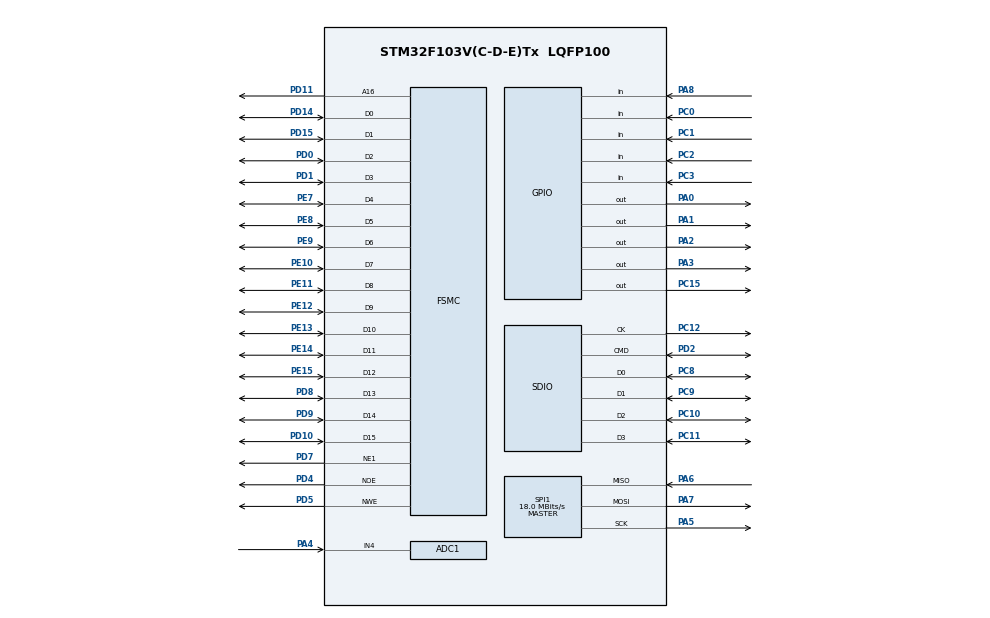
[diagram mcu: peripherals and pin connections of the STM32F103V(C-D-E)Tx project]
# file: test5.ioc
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ADC1.Channel-0\#ChannelRegularConversion=ADC_CHANNEL_4
ADC1.NbrOfConversionFlag=1
ADC1.Rank-0\#ChannelRegularConversion=1
ADC1.SamplingTime-0\#ChannelRegularConversion=ADC_SAMPLETIME_1CYCLE_5
ADC1.master=1
FATFS.BSP.number=1
FATFS._CODE_PAGE=936
FATFS._USE_LFN=2
FATFS0.BSP.STBoard=false
FATFS0.BSP.api=Unknown
FATFS0.BSP.i2caddr=0
FATFS0.BSP.instance=PA8
FATFS0.BSP.ip=GPIO
FATFS0.BSP.mode=Input
FATFS0.BSP.name=Detect_SDIO
FATFS0.BSP.solution=PA8
FREERTOS.Tasks01=defaultTask,24,128,StartDefaultTask,Default,NULL,Dynamic,NULL,NULL
FREERTOS.configUSE_NEWLIB_REENTRANT=1
FSMC.AddressSetupTime1=1
FSMC.BusTurnAroundDuration1=0
FSMC.DataSetupTime1=16
Mcu.Family=STM32F1
Mcu.Name=STM32F103V(C-D-E)Tx
Mcu.Package=LQFP100
NVIC.PriorityGroup=NVIC_PRIORITYGROUP_4
NVIC.TIM1_UP_IRQn=true\:15\:0\:false\:false\:true\:false\:false\:true
NVIC.TimeBase=TIM1_UP_IRQn
NVIC.TimeBaseIP=TIM1
OSC_IN.Mode=HSE-External-Clock-Source
OSC_IN.Signal=RCC_OSC_IN
OSC_OUT.Mode=HSE-External-Clock-Source
OSC_OUT.Signal=RCC_OSC_OUT
PA0-WKUP.GPIO_ModeDefaultOutputPP=GPIO_MODE_OUTPUT_PP
PA0-WKUP.GPIO_PuPd=GPIO_PULLUP
PA0-WKUP.GPIO_Speed=GPIO_SPEED_FREQ_HIGH
PA0-WKUP.PinState=GPIO_PIN_SET
PA0-WKUP.Signal=GPIO_Output
PA1.GPIO_ModeDefaultOutputPP=GPIO_MODE_OUTPUT_PP
PA1.GPIO_PuPd=GPIO_PULLUP
PA1.GPIO_Speed=GPIO_SPEED_FREQ_HIGH
PA1.PinState=GPIO_PIN_SET
PA1.Signal=GPIO_Output
PA13.Mode=Serial_Wire
PA13.Signal=SYS_JTMS-SWDIO
PA14.Mode=Serial_Wire
PA14.Signal=SYS_JTCK-SWCLK
PA2.GPIO_ModeDefaultOutputPP=GPIO_MODE_OUTPUT_PP
PA2.GPIO_PuPd=GPIO_PULLUP
PA2.GPIO_Speed=GPIO_SPEED_FREQ_HIGH
PA2.PinState=GPIO_PIN_SET
PA2.Signal=GPIO_Output
PA3.GPIO_ModeDefaultOutputPP=GPIO_MODE_OUTPUT_PP
PA3.GPIO_PuPd=GPIO_PULLUP
PA3.GPIO_Speed=GPIO_SPEED_FREQ_HIGH
PA3.PinState=GPIO_PIN_SET
PA3.Signal=GPIO_Output
PA4.Signal=ADCx_IN4
PA5.Mode=Full_Duplex_Master
PA5.Signal=SPI1_SCK
PA6.Mode=Full_Duplex_Master
PA6.Signal=SPI1_MISO
PA7.Mode=Full_Duplex_Master
PA7.Signal=SPI1_MOSI
PA8.GPIO_PuPd=GPIO_PULLDOWN
PA8.Signal=GPIO_Input
PC0.GPIO_Mode=GPIO_MODE_INPUT
PC0.GPIO_PuPd=GPIO_PULLUP
PC0.Signal=GPIO_Input
PC1.GPIO_Mode=GPIO_MODE_INPUT
PC1.GPIO_PuPd=GPIO_PULLUP
PC1.Signal=GPIO_Input
PC10.Mode=SD_4_bits_Wide_bus
PC10.Signal=SDIO_D2
PC11.Mode=SD_4_bits_Wide_bus
PC11.Signal=SDIO_D3
PC12.Mode=SD_4_bits_Wide_bus
PC12.Signal=SDIO_CK
PC15-OSC32_OUT.GPIO_PuPd=GPIO_PULLUP
PC15-OSC32_OUT.GPIO_Speed=GPIO_SPEED_FREQ_HIGH
PC15-OSC32_OUT.PinState=GPIO_PIN_SET
PC15-OSC32_OUT.Signal=GPIO_Output
PC2.GPIO_Mode=GPIO_MODE_INPUT
PC2.GPIO_PuPd=GPIO_PULLUP
PC2.Signal=GPIO_Input
PC3.GPIO_Mode=GPIO_MODE_INPUT
PC3.GPIO_PuPd=GPIO_PULLUP
PC3.Signal=GPIO_Input
PC8.Mode=SD_4_bits_Wide_bus
PC8.Signal=SDIO_D0
PC9.Mode=SD_4_bits_Wide_bus
PC9.Signal=SDIO_D1
PD0.Mode=16b-d1
PD0.Signal=FSMC_D2
PD1.Mode=16b-d1
PD1.Signal=FSMC_D3
PD10.Mode=16b-d1
PD10.Signal=FSMC_D15
PD11.Mode=A16_1
PD11.Signal=FSMC_A16
PD14.Mode=16b-d1
PD14.Signal=FSMC_D0
PD15.Mode=16b-d1
PD15.Signal=FSMC_D1
PD2.Mode=SD_4_bits_Wide_bus
PD2.Signal=SDIO_CMD
PD4.Mode=Lcd1
PD4.Signal=FSMC_NOE
PD5.Mode=Lcd1
PD5.Signal=FSMC_NWE
PD7.Mode=NorPsramChipSelect1_1
PD7.Signal=FSMC_NE1
PD8.Mode=16b-d1
PD8.Signal=FSMC_D13
PD9.Mode=16b-d1
PD9.Signal=FSMC_D14
PE10.Mode=16b-d1
PE10.Signal=FSMC_D7
PE11.Mode=16b-d1
PE11.Signal=FSMC_D8
PE12.Mode=16b-d1
PE12.Signal=FSMC_D9
PE13.Mode=16b-d1
PE13.Signal=FSMC_D10
PE14.Mode=16b-d1
PE14.Signal=FSMC_D11
PE15.Mode=16b-d1
PE15.Signal=FSMC_D12
PE7.Mode=16b-d1
PE7.Signal=FSMC_D4
PE8.Mode=16b-d1
PE8.Signal=FSMC_D5
PE9.Mode=16b-d1
PE9.Signal=FSMC_D6
ProjectManager.HeapSize=0x200
ProjectManager.StackSize=0x800
ProjectManager.TargetToolchain=STM32CubeIDE
RCC.ADCPresc=RCC_ADCPCLK2_DIV6
RCC.AHBFreq_Value=72000000
RCC.APB1CLKDivider=RCC_HCLK_DIV2
RCC.APB1Freq_Value=36000000
RCC.APB1TimFreq_Value=72000000
RCC.APB2Freq_Value=72000000
RCC.APB2TimFreq_Value=72000000
RCC.EnbaleCSS=true
RCC.HCLKFreq_Value=72000000
RCC.PLLMUL=RCC_PLL_MUL9
RCC.PLLSourceVirtual=RCC_PLLSOURCE_HSE
RCC.SYSCLKFreq_VALUE=72000000
RCC.SYSCLKSource=RCC_SYSCLKSOURCE_PLLCLK
RCC.USBFreq_Value=72000000
SH.ADCx_IN4.0=ADC1_IN4,IN4
SPI1.BaudRatePrescaler=SPI_BAUDRATEPRESCALER_4
SPI1.CLKPhase=SPI_PHASE_2EDGE
SPI1.CLKPolarity=SPI_POLARITY_HIGH
SPI1.CRCCalculation=SPI_CRCCALCULATION_DISABLE
SPI1.CalculateBaudRate=18.0 MBits/s
SPI1.Direction=SPI_DIRECTION_2LINES
SPI1.Mode=SPI_MODE_MASTER
SPI1.VirtualType=VM_MASTER
VP_CRC_VS_CRC.Mode=CRC_Activate
VP_FATFS_VS_SDIO.Mode=SDIO
VP_FREERTOS_VS_CMSIS_V2.Mode=CMSIS_V2
VP_SYS_VS_tim1.Mode=TIM1
board=custom

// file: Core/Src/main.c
/* USER CODE BEGIN Header */
/**
  ******************************************************************************
  * @file           : main.c
  * @brief          : Main program body
  ******************************************************************************
  * @attention
  *
  * <h2><center>&copy; Copyright (c) 2021 STMicroelectronics.
  * All rights reserved.</center></h2>
  *
  * This software component is licensed by ST under Ultimate Liberty license
  * SLA0044, the "License"; You may not use this file except in compliance with
  * the License. You may obtain a copy of the License at:
  *                             www.st.com/SLA0044
  *
  ******************************************************************************
  */
/* USER CODE END Header */
#include "main.h"
#include "cmsis_os.h"
#include "fatfs.h"
#include "exfuns/exfuns.h"
#include "lcd/lcd.h"
#include "mp3player/mp3player.h"
#include "show/show.h"

SD_HandleTypeDef hsd;

SRAM_HandleTypeDef hsram1;

/* Definitions for defaultTask */
osThreadId_t defaultTaskHandle;
const osThreadAttr_t defaultTask_attributes = {
    .name = "defaultTask",
    .stack_size = 128 * 4,
    .priority = (osPriority_t)osPriorityNormal,
};
osThreadId_t mp3TaskHandle;
const osThreadAttr_t mp3Task_attributes = {
    .name = "mp3 Task",
    .stack_size = 128 * 4,
    .priority = (osPriority_t)osPriorityNormal,
};
osThreadId_t showTaskHandle;
const osThreadAttr_t showTask_attributes = {
    .name = "show Task",
    .stack_size = 128 * 4,
    .priority = (osPriority_t)osPriorityNormal,
};

void SystemClock_Config(void);
void StartDefaultTask(void *argument);

int main(void)
{

  /* MCU Configuration--------------------------------------------------------*/

  /* Reset of all peripherals, Initializes the Flash interface and the Systick. */
  HAL_Init();

  /* Configure the system clock */
  SystemClock_Config();

  /* Initialize all configured peripherals */
  MX_GPIO_Init();
  MX_CRC_Init();
  MX_SDIO_SD_Init();
  MX_FATFS_Init();
  MX_FSMC_Init();
  MX_SPI1_Init();
  MX_ADC1_Init();
  /* USER CODE BEGIN 2 */
  LL_SPI_Enable(SPI1);
  LL_ADC_Enable(ADC1);
  LL_ADC_StartCalibration(ADC1);
  while (LL_ADC_IsCalibrationOnGoing(ADC1))
    ;
  while (exfuns_init()) //为fatfs相关变量申请内存
  {
    LCD_ShowString(30, 20, 320, 16, 16, "Fatfs -> ERROR!");
  }
  /* USER CODE END 2 */

  /* Init scheduler */
  osKernelInitialize();

  /* Create the thread(s) */
  /* creation of defaultTask */
  defaultTaskHandle = osThreadNew(StartDefaultTask, NULL, &defaultTask_attributes);

  /* Start scheduler */
  osKernelStart();

  /* We should never get here as control is now taken by the scheduler */
  /* Infinite loop */
  while (1)
  {

  }
}

void SystemClock_Config(void)
{
  LL_FLASH_SetLatency(LL_FLASH_LATENCY_2);
  while (LL_FLASH_GetLatency() != LL_FLASH_LATENCY_2)
  {
  }
  LL_RCC_HSE_EnableBypass();
  LL_RCC_HSE_Enable();

  /* Wait till HSE is ready */
  while (LL_RCC_HSE_IsReady() != 1)
  {
  }
  LL_RCC_HSE_EnableCSS();
  LL_RCC_PLL_ConfigDomain_SYS(LL_RCC_PLLSOURCE_HSE_DIV_1, LL_RCC_PLL_MUL_9);
  LL_RCC_PLL_Enable();

  /* Wait till PLL is ready */
  while (LL_RCC_PLL_IsReady() != 1)
  {
  }
  LL_RCC_SetAHBPrescaler(LL_RCC_SYSCLK_DIV_1);
  LL_RCC_SetAPB1Prescaler(LL_RCC_APB1_DIV_2);
  LL_RCC_SetAPB2Prescaler(LL_RCC_APB2_DIV_1);
  LL_RCC_SetSysClkSource(LL_RCC_SYS_CLKSOURCE_PLL);

  /* Wait till System clock is ready */
  while (LL_RCC_GetSysClkSource() != LL_RCC_SYS_CLKSOURCE_STATUS_PLL)
  {
  }
  LL_SetSystemCoreClock(72000000);

  /* Update the time base */
  if (HAL_InitTick(TICK_INT_PRIORITY) != HAL_OK)
  {
    Error_Handler();
  }
  LL_RCC_SetADCClockSource(LL_RCC_ADC_CLKSRC_PCLK2_DIV_6);
}

void MX_ADC1_Init(void)
{

  LL_ADC_InitTypeDef ADC_InitStruct = {0};
  LL_ADC_CommonInitTypeDef ADC_CommonInitStruct = {0};
  LL_ADC_REG_InitTypeDef ADC_REG_InitStruct = {0};

  LL_GPIO_InitTypeDef GPIO_InitStruct = {0};

  /* Peripheral clock enable */
  LL_APB2_GRP1_EnableClock(LL_APB2_GRP1_PERIPH_ADC1);

  LL_APB2_GRP1_EnableClock(LL_APB2_GRP1_PERIPH_GPIOA);
  /**ADC1 GPIO Configuration
  PA4   ------> ADC1_IN4
  */
  GPIO_InitStruct.Pin = LL_GPIO_PIN_4;
  GPIO_InitStruct.Mode = LL_GPIO_MODE_ANALOG;
  LL_GPIO_Init(GPIOA, &GPIO_InitStruct);

  /** Common config
  */
  ADC_InitStruct.DataAlignment = LL_ADC_DATA_ALIGN_RIGHT;
  ADC_InitStruct.SequencersScanMode = LL_ADC_SEQ_SCAN_DISABLE;
  LL_ADC_Init(ADC1, &ADC_InitStruct);
  ADC_CommonInitStruct.Multimode = LL_ADC_MULTI_INDEPENDENT;
  LL_ADC_CommonInit(__LL_ADC_COMMON_INSTANCE(ADC1), &ADC_CommonInitStruct);
  ADC_REG_InitStruct.TriggerSource = LL_ADC_REG_TRIG_SOFTWARE;
  ADC_REG_InitStruct.SequencerLength = LL_ADC_REG_SEQ_SCAN_DISABLE;
  ADC_REG_InitStruct.SequencerDiscont = LL_ADC_REG_SEQ_DISCONT_DISABLE;
  ADC_REG_InitStruct.ContinuousMode = LL_ADC_REG_CONV_SINGLE;
  ADC_REG_InitStruct.DMATransfer = LL_ADC_REG_DMA_TRANSFER_NONE;
  LL_ADC_REG_Init(ADC1, &ADC_REG_InitStruct);
  /** Configure Regular Channel
  */
  LL_ADC_REG_SetSequencerRanks(ADC1, LL_ADC_REG_RANK_1, LL_ADC_CHANNEL_4);
  LL_ADC_SetChannelSamplingTime(ADC1, LL_ADC_CHANNEL_4, LL_ADC_SAMPLINGTIME_1CYCLE_5);
}

void MX_CRC_Init(void)
{

  /* Peripheral clock enable */
  LL_AHB1_GRP1_EnableClock(LL_AHB1_GRP1_PERIPH_CRC);

}

void MX_SDIO_SD_Init(void)
{

  hsd.Instance = SDIO;
  hsd.Init.ClockEdge = SDIO_CLOCK_EDGE_RISING;
  hsd.Init.ClockBypass = SDIO_CLOCK_BYPASS_DISABLE;
  hsd.Init.ClockPowerSave = SDIO_CLOCK_POWER_SAVE_DISABLE;
  hsd.Init.BusWide = SDIO_BUS_WIDE_1B;
  hsd.Init.HardwareFlowControl = SDIO_HARDWARE_FLOW_CONTROL_DISABLE;
  hsd.Init.ClockDiv = 0;
}

void MX_SPI1_Init(void)
{

  LL_SPI_InitTypeDef SPI_InitStruct = {0};

  LL_GPIO_InitTypeDef GPIO_InitStruct = {0};

  /* Peripheral clock enable */
  LL_APB2_GRP1_EnableClock(LL_APB2_GRP1_PERIPH_SPI1);

  LL_APB2_GRP1_EnableClock(LL_APB2_GRP1_PERIPH_GPIOA);
  /**SPI1 GPIO Configuration
  PA5   ------> SPI1_SCK
  PA6   ------> SPI1_MISO
  PA7   ------> SPI1_MOSI
  */
  GPIO_InitStruct.Pin = LL_GPIO_PIN_5 | LL_GPIO_PIN_7;
  GPIO_InitStruct.Mode = LL_GPIO_MODE_ALTERNATE;
  GPIO_InitStruct.Speed = LL_GPIO_SPEED_FREQ_HIGH;
  GPIO_InitStruct.OutputType = LL_GPIO_OUTPUT_PUSHPULL;
  LL_GPIO_Init(GPIOA, &GPIO_InitStruct);

  GPIO_InitStruct.Pin = LL_GPIO_PIN_6;
  GPIO_InitStruct.Mode = LL_GPIO_MODE_FLOATING;
  LL_GPIO_Init(GPIOA, &GPIO_InitStruct);

  /* SPI1 parameter configuration*/
  SPI_InitStruct.TransferDirection = LL_SPI_FULL_DUPLEX;
  SPI_InitStruct.Mode = LL_SPI_MODE_MASTER;
  SPI_InitStruct.DataWidth = LL_SPI_DATAWIDTH_8BIT;
  SPI_InitStruct.ClockPolarity = LL_SPI_POLARITY_HIGH;
  SPI_InitStruct.ClockPhase = LL_SPI_PHASE_2EDGE;
  SPI_InitStruct.NSS = LL_SPI_NSS_SOFT;
  SPI_InitStruct.BaudRate = LL_SPI_BAUDRATEPRESCALER_DIV4;
  SPI_InitStruct.BitOrder = LL_SPI_MSB_FIRST;
  SPI_InitStruct.CRCCalculation = LL_SPI_CRCCALCULATION_DISABLE;
  SPI_InitStruct.CRCPoly = 10;
  LL_SPI_Init(SPI1, &SPI_InitStruct);
}

void MX_GPIO_Init(void)
{
  LL_GPIO_InitTypeDef GPIO_InitStruct = {0};

  /* GPIO Ports Clock Enable */
  LL_APB2_GRP1_EnableClock(LL_APB2_GRP1_PERIPH_GPIOC);
  LL_APB2_GRP1_EnableClock(LL_APB2_GRP1_PERIPH_GPIOA);
  LL_APB2_GRP1_EnableClock(LL_APB2_GRP1_PERIPH_GPIOE);
  LL_APB2_GRP1_EnableClock(LL_APB2_GRP1_PERIPH_GPIOD);

  /**/
  LL_GPIO_SetOutputPin(GPIOC, LL_GPIO_PIN_15);

  /**/
  LL_GPIO_SetOutputPin(GPIOA, LL_GPIO_PIN_0 | LL_GPIO_PIN_1 | LL_GPIO_PIN_2 | LL_GPIO_PIN_3);

  /**/
  GPIO_InitStruct.Pin = LL_GPIO_PIN_15;
  GPIO_InitStruct.Mode = LL_GPIO_MODE_OUTPUT;
  GPIO_InitStruct.Speed = LL_GPIO_SPEED_FREQ_HIGH;
  GPIO_InitStruct.OutputType = LL_GPIO_OUTPUT_PUSHPULL;
  GPIO_InitStruct.Pull = LL_GPIO_PULL_UP;
  LL_GPIO_Init(GPIOC, &GPIO_InitStruct);

  /**/
  GPIO_InitStruct.Pin = LL_GPIO_PIN_0 | LL_GPIO_PIN_1 | LL_GPIO_PIN_2 | LL_GPIO_PIN_3;
  GPIO_InitStruct.Mode = LL_GPIO_MODE_INPUT;
  GPIO_InitStruct.Pull = LL_GPIO_PULL_UP;
  LL_GPIO_Init(GPIOC, &GPIO_InitStruct);

  /**/
  GPIO_InitStruct.Pin = LL_GPIO_PIN_0 | LL_GPIO_PIN_1 | LL_GPIO_PIN_2 | LL_GPIO_PIN_3;
  GPIO_InitStruct.Mode = LL_GPIO_MODE_OUTPUT;
  GPIO_InitStruct.Speed = LL_GPIO_SPEED_FREQ_HIGH;
  GPIO_InitStruct.OutputType = LL_GPIO_OUTPUT_PUSHPULL;
  GPIO_InitStruct.Pull = LL_GPIO_PULL_UP;
  LL_GPIO_Init(GPIOA, &GPIO_InitStruct);

  /**/
  GPIO_InitStruct.Pin = LL_GPIO_PIN_8;
  GPIO_InitStruct.Mode = LL_GPIO_MODE_INPUT;
  GPIO_InitStruct.Pull = LL_GPIO_PULL_DOWN;
  LL_GPIO_Init(GPIOA, &GPIO_InitStruct);
}

/* FSMC initialization function */
void MX_FSMC_Init(void)
{

  FSMC_NORSRAM_TimingTypeDef Timing = {0};

  /** Perform the SRAM1 memory initialization sequence
  */
  hsram1.Instance = FSMC_NORSRAM_DEVICE;
  hsram1.Extended = FSMC_NORSRAM_EXTENDED_DEVICE;
  /* hsram1.Init */
  hsram1.Init.NSBank = FSMC_NORSRAM_BANK1;
  hsram1.Init.DataAddressMux = FSMC_DATA_ADDRESS_MUX_DISABLE;
  hsram1.Init.MemoryType = FSMC_MEMORY_TYPE_SRAM;
  hsram1.Init.MemoryDataWidth = FSMC_NORSRAM_MEM_BUS_WIDTH_16;
  hsram1.Init.BurstAccessMode = FSMC_BURST_ACCESS_MODE_DISABLE;
  hsram1.Init.WaitSignalPolarity = FSMC_WAIT_SIGNAL_POLARITY_LOW;
  hsram1.Init.WrapMode = FSMC_WRAP_MODE_DISABLE;
  hsram1.Init.WaitSignalActive = FSMC_WAIT_TIMING_BEFORE_WS;
  hsram1.Init.WriteOperation = FSMC_WRITE_OPERATION_ENABLE;
  hsram1.Init.WaitSignal = FSMC_WAIT_SIGNAL_DISABLE;
  hsram1.Init.ExtendedMode = FSMC_EXTENDED_MODE_DISABLE;
  hsram1.Init.AsynchronousWait = FSMC_ASYNCHRONOUS_WAIT_DISABLE;
  hsram1.Init.WriteBurst = FSMC_WRITE_BURST_DISABLE;
  /* Timing */
  Timing.AddressSetupTime = 1;
  Timing.AddressHoldTime = 15;
  Timing.DataSetupTime = 16;
  Timing.BusTurnAroundDuration = 0;
  Timing.CLKDivision = 16;
  Timing.DataLatency = 17;
  Timing.AccessMode = FSMC_ACCESS_MODE_A;
  /* ExtTiming */

  if (HAL_SRAM_Init(&hsram1, &Timing, NULL) != HAL_OK)
  {
    Error_Handler();
  }

  /** Disconnect NADV
  */

  __HAL_AFIO_FSMCNADV_DISCONNECTED();

}

void StartDefaultTask(void *argument)
{
  /* USER CODE BEGIN 5 */
  mp3TaskHandle = osThreadNew(mp3_play, NULL, &mp3Task_attributes);
  showTaskHandle = osThreadNew(show_mp3_pic, NULL, &showTask_attributes);
  /* Infinite loop */
  for (;;)
  {
    osDelay(1);
  }
  /* USER CODE END 5 */
}

void HAL_TIM_PeriodElapsedCallback(TIM_HandleTypeDef *htim)
{
  if (htim->Instance == TIM1)
  {
    HAL_IncTick();
  }
}

void Error_Handler(void)
{
  __disable_irq();
  while (1)
  {
  }
}

/************************ (C) COPYRIGHT STMicroelectronics *****END OF FILE****/
